VERSION ""

NS_ :

BS_:

BU_: Vector__XXX

BO_ 192 TelemLeader_Center: 8 Vector__XXX
	SG_ Timestamp : 0|16@1+ (1,0) [0|65535] "" Vector__XXX

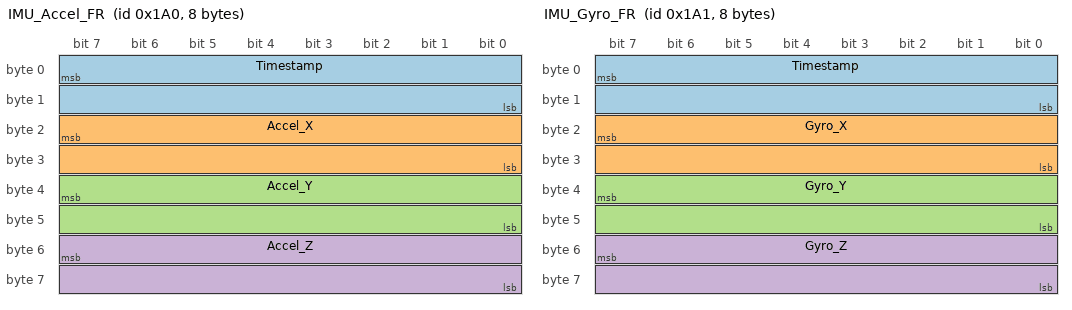
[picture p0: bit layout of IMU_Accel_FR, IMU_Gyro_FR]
BO_ 416 IMU_Accel_FR: 8 Vector__XXX
	SG_ Timestamp : 7|16@0+ (1,0) [0|65535] "" Vector__XXX
	SG_ Accel_X : 23|16@0+ (1,0) [0|65535] "" Vector__XXX
	SG_ Accel_Y : 39|16@0+ (1,0) [0|65535] "" Vector__XXX
	SG_ Accel_Z : 55|16@0+ (1,0) [0|65535] "" Vector__XXX

BO_ 417 IMU_Gyro_FR: 8 Vector__XXX
	SG_ Timestamp : 7|16@0+ (1,0) [0|65535] "" Vector__XXX
	SG_ Gyro_X : 23|16@0+ (1,0) [0|65535] "" Vector__XXX
	SG_ Gyro_Y : 39|16@0+ (1,0) [0|65535] "" Vector__XXX
	SG_ Gyro_Z : 55|16@0+ (1,0) [0|65535] "" Vector__XXX

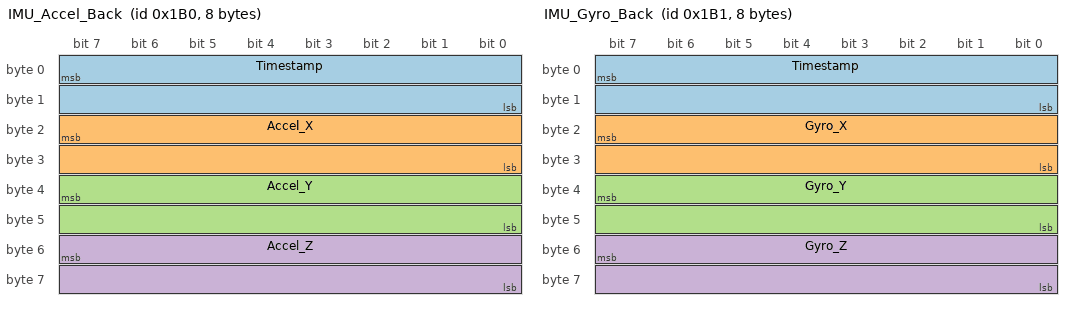
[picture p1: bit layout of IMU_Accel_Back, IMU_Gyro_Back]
BO_ 432 IMU_Accel_Back: 8 Vector__XXX
	SG_ Timestamp : 7|16@0+ (1,0) [0|65535] "" Vector__XXX
	SG_ Accel_X : 23|16@0+ (1,0) [0|65535] "" Vector__XXX
	SG_ Accel_Y : 39|16@0+ (1,0) [0|65535] "" Vector__XXX
	SG_ Accel_Z : 55|16@0+ (1,0) [0|65535] "" Vector__XXX

BO_ 433 IMU_Gyro_Back: 8 Vector__XXX
	SG_ Timestamp : 7|16@0+ (1,0) [0|65535] "" Vector__XXX
	SG_ Gyro_X : 23|16@0+ (1,0) [0|65535] "" Vector__XXX
	SG_ Gyro_Y : 39|16@0+ (1,0) [0|65535] "" Vector__XXX
	SG_ Gyro_Z : 55|16@0+ (1,0) [0|65535] "" Vector__XXX

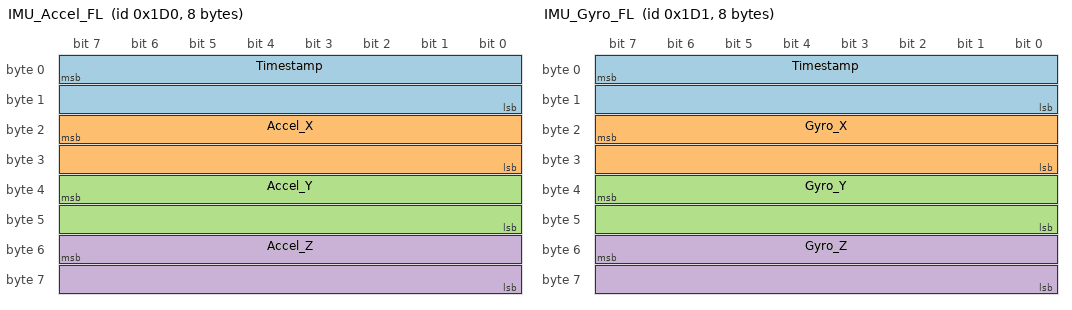
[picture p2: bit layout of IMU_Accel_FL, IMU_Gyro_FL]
BO_ 464 IMU_Accel_FL: 8 Vector__XXX
	SG_ Timestamp : 7|16@0+ (1,0) [0|65535] "" Vector__XXX
	SG_ Accel_X : 23|16@0+ (1,0) [0|65535] "" Vector__XXX
	SG_ Accel_Y : 39|16@0+ (1,0) [0|65535] "" Vector__XXX
	SG_ Accel_Z : 55|16@0+ (1,0) [0|65535] "" Vector__XXX

BO_ 465 IMU_Gyro_FL: 8 Vector__XXX
	SG_ Timestamp : 7|16@0+ (1,0) [0|65535] "" Vector__XXX
	SG_ Gyro_X : 23|16@0+ (1,0) [0|65535] "" Vector__XXX
	SG_ Gyro_Y : 39|16@0+ (1,0) [0|65535] "" Vector__XXX
	SG_ Gyro_Z : 55|16@0+ (1,0) [0|65535] "" Vector__XXX

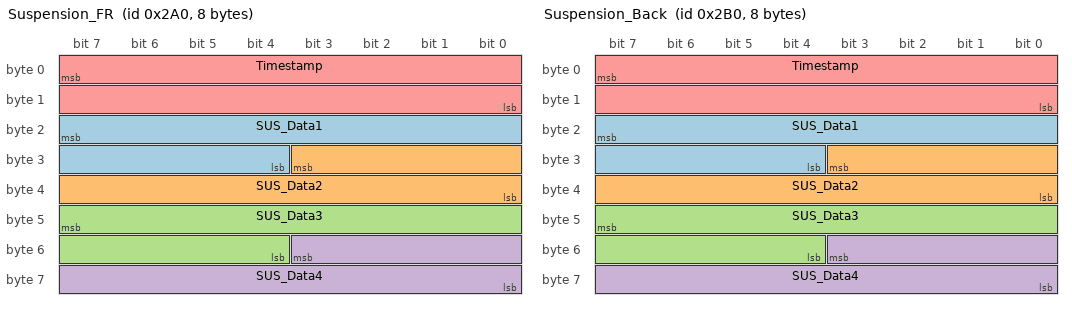
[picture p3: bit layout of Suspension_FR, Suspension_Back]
BO_ 672 Suspension_FR: 8 Vector__XXX
	SG_ SUS_Data1 : 23|12@0+ (1,0) [0|4095] "" Vector__XXX
	SG_ SUS_Data2 : 27|12@0+ (1,0) [0|4095] "" Vector__XXX
	SG_ SUS_Data3 : 47|12@0+ (1,0) [0|4095] "" Vector__XXX
	SG_ SUS_Data4 : 51|12@0+ (1,0) [0|4095] "" Vector__XXX
	SG_ Timestamp : 7|16@0+ (1,0) [0|65535] "" Vector__XXX

BO_ 688 Suspension_Back: 8 Vector__XXX
	SG_ SUS_Data1 : 23|12@0+ (1,0) [0|4095] "" Vector__XXX
	SG_ SUS_Data2 : 27|12@0+ (1,0) [0|4095] "" Vector__XXX
	SG_ SUS_Data3 : 47|12@0+ (1,0) [0|4095] "" Vector__XXX
	SG_ SUS_Data4 : 51|12@0+ (1,0) [0|4095] "" Vector__XXX
	SG_ Timestamp : 7|16@0+ (1,0) [0|65535] "" Vector__XXX

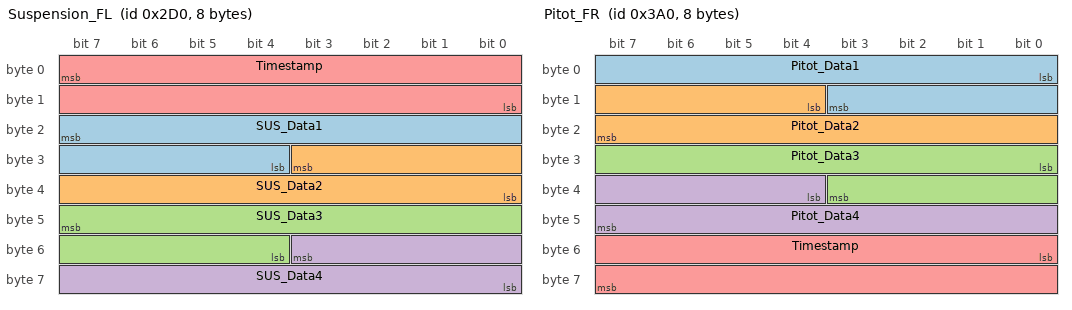
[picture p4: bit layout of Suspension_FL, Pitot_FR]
BO_ 720 Suspension_FL: 8 Vector__XXX
	SG_ SUS_Data1 : 23|12@0+ (1,0) [0|4095] "" Vector__XXX
	SG_ SUS_Data2 : 27|12@0+ (1,0) [0|4095] "" Vector__XXX
	SG_ SUS_Data3 : 47|12@0+ (1,0) [0|4095] "" Vector__XXX
	SG_ SUS_Data4 : 51|12@0+ (1,0) [0|4095] "" Vector__XXX
	SG_ Timestamp : 7|16@0+ (1,0) [0|65535] "" Vector__XXX

BO_ 928 Pitot_FR: 8 Vector__XXX
	SG_ Pitot_Data1 : 0|12@1+ (1,0) [0|4095] "" Vector__XXX
	SG_ Pitot_Data2 : 12|12@1+ (1,0) [0|4095] "" Vector__XXX
	SG_ Pitot_Data3 : 24|12@1+ (1,0) [0|4095] "" Vector__XXX
	SG_ Pitot_Data4 : 36|12@1+ (1,0) [0|4095] "" Vector__XXX
	SG_ Timestamp : 48|16@1+ (1,0) [0|65535] "" Vector__XXX

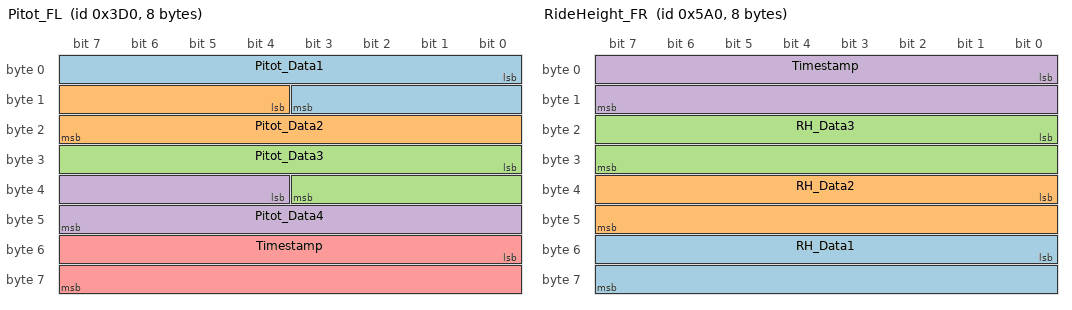
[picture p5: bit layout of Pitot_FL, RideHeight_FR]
BO_ 976 Pitot_FL: 8 Vector__XXX
	SG_ Pitot_Data1 : 0|12@1+ (1,0) [0|4095] "" Vector__XXX
	SG_ Pitot_Data2 : 12|12@1+ (1,0) [0|4095] "" Vector__XXX
	SG_ Pitot_Data3 : 24|12@1+ (1,0) [0|4095] "" Vector__XXX
	SG_ Pitot_Data4 : 36|12@1+ (1,0) [0|4095] "" Vector__XXX
	SG_ Timestamp : 48|16@1+ (1,0) [0|65535] "" Vector__XXX

BO_ 1184 WheelRPM_FR: 8 Vector__XXX
	SG_ RPM : 0|16@1+ (1,0) [0|65535] "" Vector__XXX
	SG_ Timestamp : 16|16@1+ (1,0) [0|65535] "" Vector__XXX

BO_ 1232 WheelRPM_FL: 8 Vector__XXX
	SG_ RPM : 0|16@1+ (1,0) [0|65535] "" Vector__XXX
	SG_ Timestamp : 16|16@1+ (1,0) [0|65535] "" Vector__XXX

BO_ 1440 RideHeight_FR: 8 Vector__XXX
	SG_ RH_Data1 : 48|16@1+ (1,0) [0|65535] "" Vector__XXX
	SG_ RH_Data2 : 32|16@1+ (1,0) [0|65535] "" Vector__XXX
	SG_ RH_Data3 : 16|16@1+ (1,0) [0|65535] "" Vector__XXX
	SG_ Timestamp : 0|16@1+ (1,0) [0|65535] "" Vector__XXX

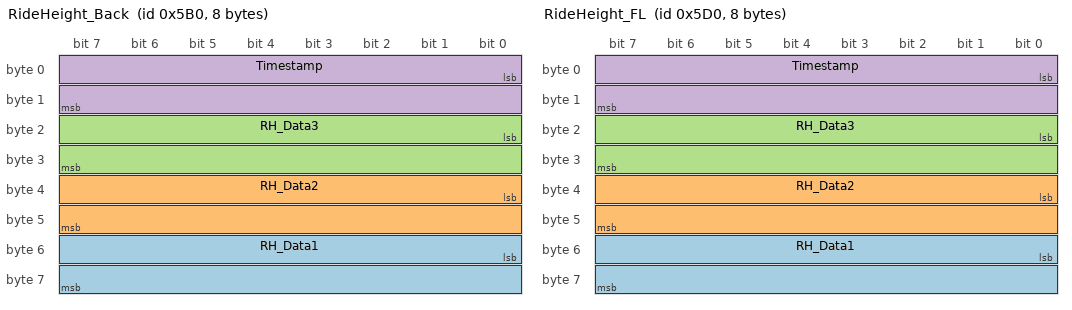
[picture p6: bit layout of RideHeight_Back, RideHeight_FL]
BO_ 1456 RideHeight_Back: 8 Vector__XXX
	SG_ RH_Data1 : 48|16@1+ (1,0) [0|65535] "" Vector__XXX
	SG_ RH_Data2 : 32|16@1+ (1,0) [0|65535] "" Vector__XXX
	SG_ RH_Data3 : 16|16@1+ (1,0) [0|65535] "" Vector__XXX
	SG_ Timestamp : 0|16@1+ (1,0) [0|65535] "" Vector__XXX

BO_ 1488 RideHeight_FL: 8 Vector__XXX
	SG_ RH_Data1 : 48|16@1+ (1,0) [0|65535] "" Vector__XXX
	SG_ RH_Data2 : 32|16@1+ (1,0) [0|65535] "" Vector__XXX
	SG_ RH_Data3 : 16|16@1+ (1,0) [0|65535] "" Vector__XXX
	SG_ Timestamp : 0|16@1+ (1,0) [0|65535] "" Vector__XXX

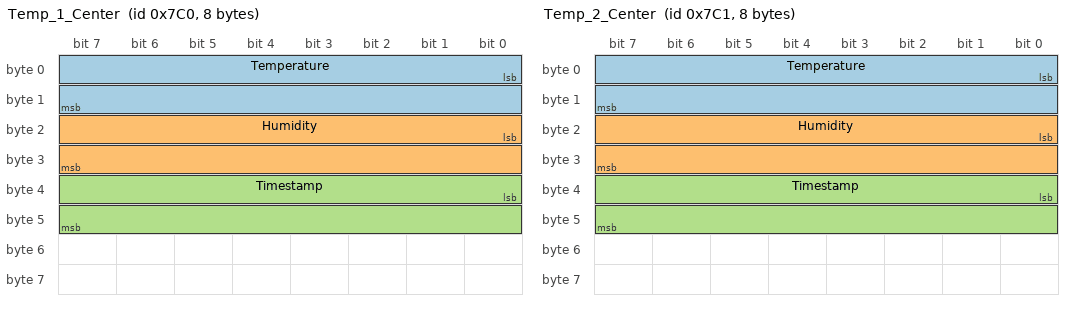
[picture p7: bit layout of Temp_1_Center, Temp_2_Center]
BO_ 1984 Temp_1_Center: 8 Vector__XXX
	SG_ Temperature : 0|16@1+ (1,0) [0|65535] "" Vector__XXX
	SG_ Humidity : 16|16@1+ (1,0) [0|65535] "" Vector__XXX
	SG_ Timestamp : 32|16@1+ (1,0) [0|65535] "" Vector__XXX

BO_ 1985 Temp_2_Center: 8 Vector__XXX
	SG_ Temperature : 0|16@1+ (1,0) [0|65535] "" Vector__XXX
	SG_ Humidity : 16|16@1+ (1,0) [0|65535] "" Vector__XXX
	SG_ Timestamp : 32|16@1+ (1,0) [0|65535] "" Vector__XXX

CM_ BO_ 192 "Telem Leader Node";
CM_ SG_ 192 Timestamp "Wheel-Based Vehicle Speed: Speed of the vehicle as calculated from wheel or tailshaft speed.";

BA_DEF_ BO_  "VFrameFormat" ENUM  "StandardCAN","ExtendedCAN","reserved","J1939PG";
BA_DEF_  "DatabaseVersion" STRING ;
BA_DEF_  "BusType" STRING ;
BA_DEF_  "ProtocolType" STRING ;
BA_DEF_  "DatabaseCompiler" STRING ;
BA_DEF_DEF_  "VFrameFormat" "J1939PG";
BA_DEF_DEF_  "DatabaseVersion" "DEMO PLUS";
BA_DEF_DEF_  "BusType" "";
BA_DEF_DEF_  "ProtocolType" "";
BA_DEF_DEF_  "DatabaseCompiler" "";
BA_ "BusType" "CAN";
BA_ "DatabaseCompiler" "CSS ELECTRONICS (WWW.CSSELECTRONICS.COM)";
BA_ "DatabaseVersion" "1.0.0";
